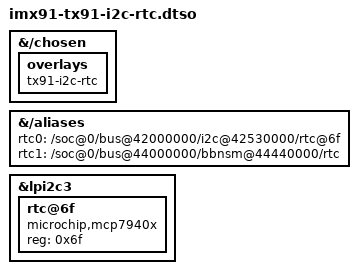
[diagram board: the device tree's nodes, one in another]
// SPDX-License-Identifier: (GPL-2.0 OR BSD-3-Clause)
/*
 * Copyright (C) 2023 Lothar Waßmann <LW@KARO-electronics.de>
 */

/dts-v1/;

/plugin/;

&{/chosen} {
	overlays {
		tx91-i2c-rtc;
	};
};

&{/aliases} {
	rtc0 = "/soc@0/bus@42000000/i2c@42530000/rtc@6f";
	rtc1 = "/soc@0/bus@44000000/bbnsm@44440000/rtc";
};

&lpi2c3 {
	#address-cells = <1>;
	#size-cells = <0>;
	status = "okay";

	rtc@6f {
		compatible = "microchip,mcp7940x";
		reg = <0x6f>;
	};
};
